# STM32F3x8 register map
File version: 1.5
CPU: CM4 r1p0, little endian, no MPU, no FPU, 3 interrupt priority bits
Registers are 32-bit, read-write, reset 0x0 unless marked. A register's access mark holds for its fields unless they carry their own. Offsets are from the block's base; [hi:lo] are bit positions; {n}, {i} and the like mark numbered series.

## PWR — Power control
Base 0x40007000
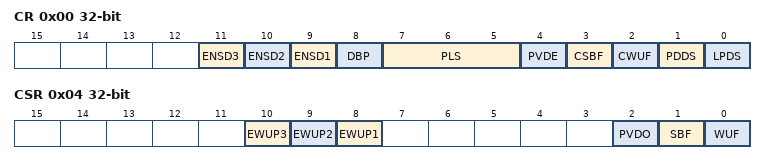
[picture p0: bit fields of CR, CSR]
0x00 CR — power control register
  [11] ENSD3 — ENable SD3 ADC
  [10] ENSD2 — ENable SD2 ADC
  [9] ENSD1 — ENable SD1 ADC
  [8] DBP — Disable backup domain write protection
  [7:5] PLS — PVD level selection
  [4] PVDE — Power voltage detector enable
  [3] CSBF — Clear standby flag
  [2] CWUF — Clear wakeup flag
  [1] PDDS — Power down deepsleep
  [0] LPDS — Low-power deep sleep
0x04 CSR access per field — power control/status register
  [10] EWUP3 rw — Enable WKUP3 pin
  [9] EWUP2 rw — Enable WKUP2 pin
  [8] EWUP1 rw — Enable WKUP1 pin
  [2] PVDO ro — PVD output
  [1] SBF ro — Standby flag
  [0] WUF ro — Wakeup flag

## USB — Universal serial bus full-speed device interface
Base 0x40005C00
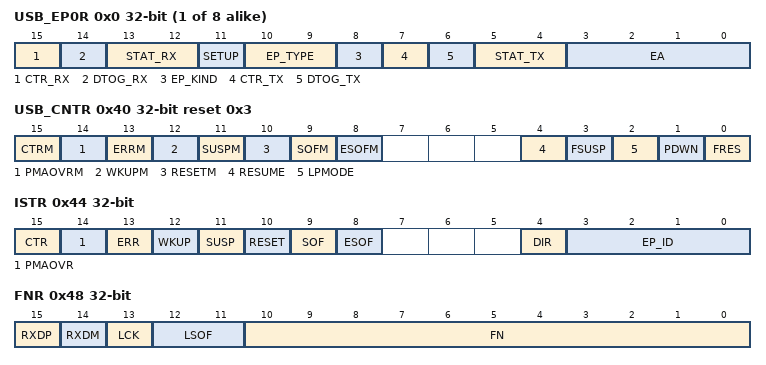
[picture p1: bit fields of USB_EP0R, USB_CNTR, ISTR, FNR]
{0x0+4i} USB_EP{i}R access per field (i=0..7) — endpoint {i} register
  [15] CTR_RX rw — Correct transfer for reception
  [14] DTOG_RX rw — Data Toggle, for reception transfers
  [13:12] STAT_RX rw — Status bits, for reception transfers
  [11] SETUP ro — Setup transaction completed
  [10:9] EP_TYPE rw — Endpoint type
  [8] EP_KIND rw — Endpoint kind
  [7] CTR_TX rw — Correct Transfer for transmission
  [6] DTOG_TX rw — Data Toggle, for transmission transfers
  [5:4] STAT_TX rw — Status bits, for transmission transfers
  [3:0] EA rw — Endpoint address
0x40 USB_CNTR reset 0x3 — control register
  [15] CTRM — Correct transfer interrupt mask
  [14] PMAOVRM — Packet memory area over / underrun interrupt mask
  [13] ERRM — Error interrupt mask
  [12] WKUPM — Wakeup interrupt mask
  [11] SUSPM — Suspend mode interrupt mask
  [10] RESETM — USB reset interrupt mask
  [9] SOFM — Start of frame interrupt mask
  [8] ESOFM — Expected start of frame interrupt mask
  [4] RESUME — Resume request
  [3] FSUSP — Force suspend
  [2] LPMODE — Low-power mode
  [1] PDWN — Power down
  [0] FRES — Force USB Reset
0x44 ISTR access per field — interrupt status register
  [15] CTR ro — Correct transfer
  [14] PMAOVR rw — Packet memory area over / underrun
  [13] ERR rw — Error
  [12] WKUP rw — Wakeup
  [11] SUSP rw — Suspend mode request
  [10] RESET rw — reset request
  [9] SOF rw — start of frame
  [8] ESOF rw — Expected start frame
  [4] DIR ro — Direction of transaction
  [3:0] EP_ID ro — Endpoint Identifier
0x48 FNR ro — frame number register
  [15] RXDP — Receive data + line status
  [14] RXDM — Receive data - line status
  [13] LCK — Locked
  [12:11] LSOF — Lost SOF
  [10:0] FN — Frame number
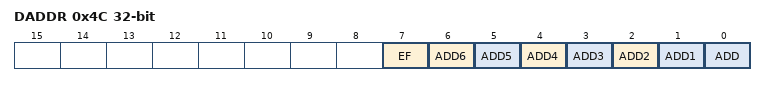
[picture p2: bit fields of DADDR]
0x4C DADDR — device address
  [7] EF — Enable function
  [n] ADD{n} (n=1..6) — Device address
  [0] ADD — Device address
0x50 BTABLE — Buffer table address
  [15:3] BTABLE — Buffer table

## IWDG — Independent watchdog
Base 0x40003000
0x00 KR wo — Key register
  [15:0] KEY — Key value
0x04 PR — Prescaler register
  [2:0] PR — Prescaler divider
0x08 RLR reset 0xFFF — Reload register
  [11:0] RL — Watchdog counter reload value
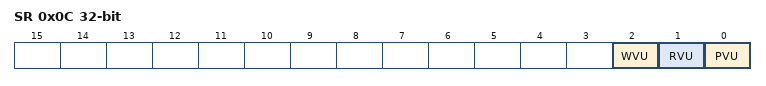
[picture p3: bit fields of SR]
0x0C SR ro — Status register
  [2] WVU — Watchdog counter window value update
  [1] RVU — Watchdog counter reload value update
  [0] PVU — Watchdog prescaler value update
0x10 WINR reset 0xFFF — Window register
  [11:0] WIN — Watchdog counter window value

## WWDG — Window watchdog
Base 0x40002C00
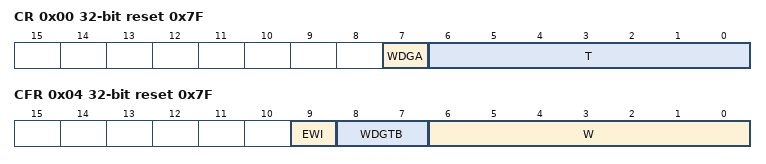
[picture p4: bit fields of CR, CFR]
0x00 CR reset 0x7F — Control register
  [7] WDGA — Activation bit
  [6:0] T — 7-bit counter
0x04 CFR reset 0x7F — Configuration register
  [9] EWI — Early wakeup interrupt
  [8:7] WDGTB — Timer base
  [6:0] W — 7-bit window value
0x08 SR — Status register
  [0] EWIF — Early wakeup interrupt flag

## DAC2 — Digital-to-analog converter
Base 0x40009800
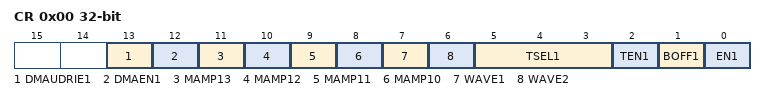
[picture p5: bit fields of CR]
0x00 CR — control register
  [13] DMAUDRIE1 — DAC channel1 DMA Underrun Interrupt enable
  [12] DMAEN1 — DAC channel1 DMA enable
  [11] MAMP13 — DAC channel1 mask/amplitude selector
  [10] MAMP12
  [9] MAMP11
  [8] MAMP10
  [7] WAVE1 — DAC channel1 noise/triangle wave generation enable
  [6] WAVE2
  [5:3] TSEL1 — DAC channel1 trigger selection
  [2] TEN1 — DAC channel1 trigger enable
  [1] BOFF1 — DAC channel1 output buffer disable
  [0] EN1 — DAC channel1 enable
0x04 SWTRIGR wo — software trigger register
  [0] SWTRIG1 — DAC channel1 software trigger
0x08 DHR12R1 — channel1 12-bit right-aligned data holding register
  [11:0] DACC1DHR — DAC channel1 12-bit right-aligned data
0x0C DHR12L1 — DAC channel1 12-bit left aligned data holding register
  [15:4] DACC1DHR — DAC channel1 12-bit left-aligned data
0x10 DHR8R1 — DAC channel1 8-bit right aligned data holding register
  [7:0] DACC1DHR — DAC channel1 8-bit right-aligned data
0x2C DOR1 ro — DAC channel1 data output register
  [11:0] DACC1DOR — DAC channel1 data output
0x34 SR — DAC status register
  [13] DMAUDR1 — DAC channel1 DMA underrun flag
